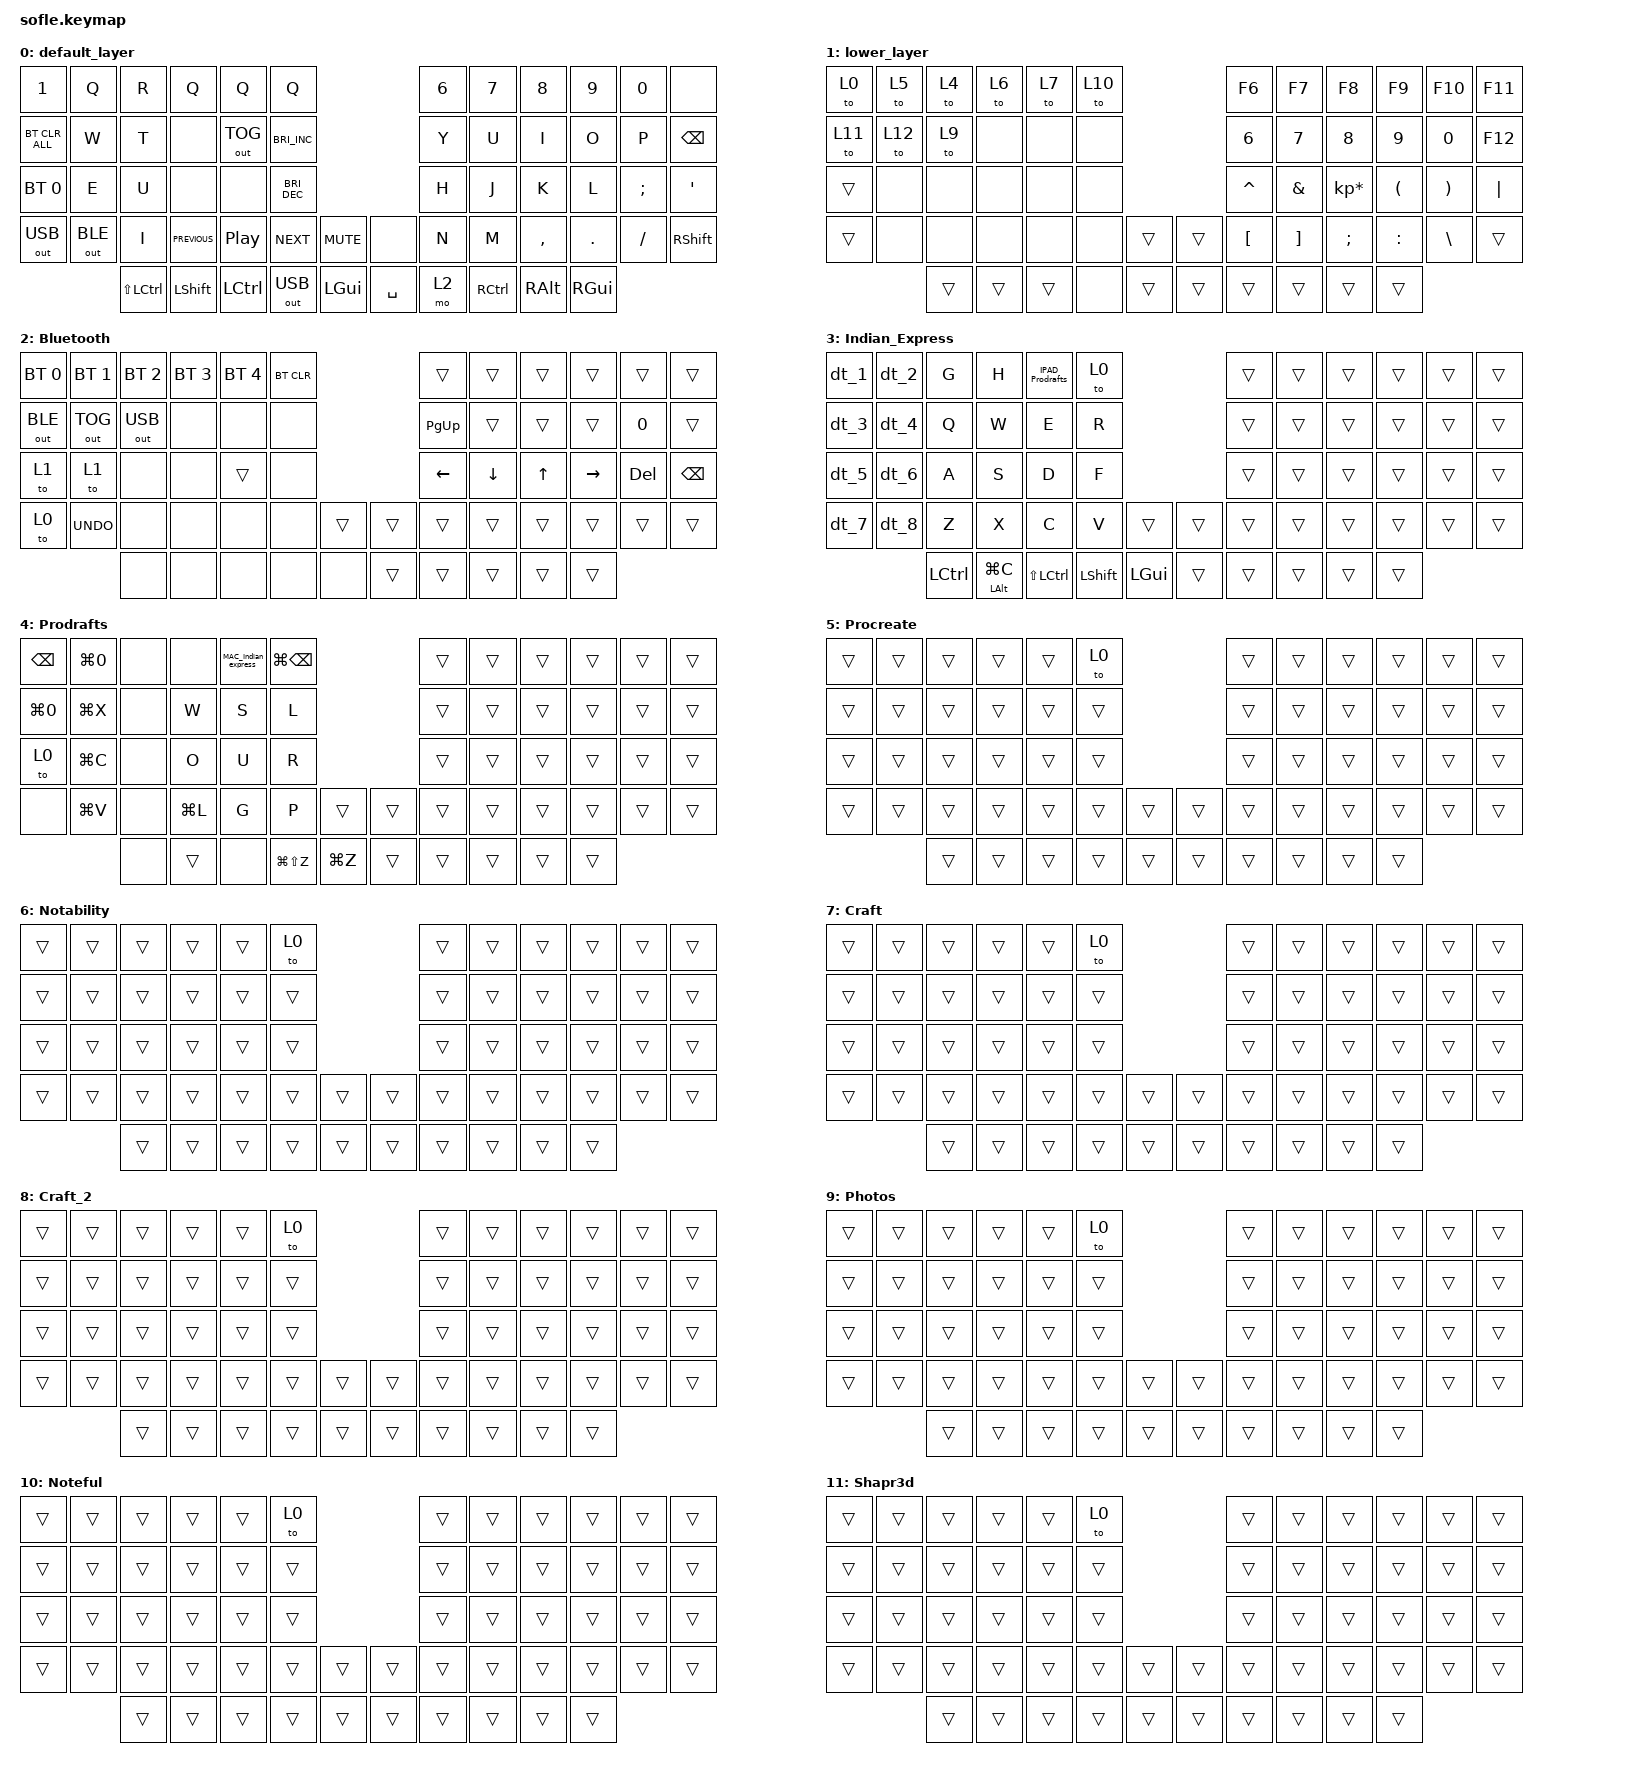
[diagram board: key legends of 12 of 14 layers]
/*
 * Copyright (c) 2020 The ZMK Contributors
 *
 * SPDX-License-Identifier: MIT
 */

#include <behaviors.dtsi>
#include <dt-bindings/zmk/bt.h>
#include <dt-bindings/zmk/keys.h>
#include <dt-bindings/zmk/outputs.h>

/ {
    combos {
        compatible = "zmk,combos";

        combo_capsw {
            timeout-ms = <50>;
            key-positions = <16 19>;
            bindings = <&caps_word>;
        };

        combo_bootl {
            timeout-ms = <50>;
            key-positions = <0 1 2>;
            bindings = <&bootloader>;
        };

        combo_reset {
            timeout-ms = <50>;
            key-positions = <10 11 12>;
            bindings = <&sys_reset>;
        };
    };

    behaviors {
        rot_td: rot_tap_dance {
            compatible = "zmk,behavior-tap-dance";
            #binding-cells = <0>;
            tapping-term-ms = <250>;
            bindings = <&kp C_PP>, <&kp C_NEXT>, <&kp C_PREV>;
        };

        ble_encoder: ble_encoder {
            compatible = "zmk,behavior-sensor-rotate";
            #sensor-binding-cells = <0>;
            bindings = <&bt BT_NXT>, <&bt BT_PRV>;
        };

        dt_1: dt_1 {
            compatible = "zmk,behavior-tap-dance";
            label = "DT_1";
            #binding-cells = <0>;
            tapping-term-ms = <250>;
            bindings = <&kp N0>, <&kp RS(N0)>, <&kp RA(N0)>;
        };

        dt_2: dt_2 {
            compatible = "zmk,behavior-tap-dance";
            label = "DT_2";
            #binding-cells = <0>;
            tapping-term-ms = <250>;
            bindings = <&kp NUMBER_2>, <&kp RS(NUMBER_2)>, <&kp RA(NUMBER_2)>;
        };

        dt_3: dt_3 {
            compatible = "zmk,behavior-tap-dance";
            label = "DT_3";
            #binding-cells = <0>;
            tapping-term-ms = <250>;
            bindings = <&kp NUMBER_3>, <&kp RS(NUMBER_3)>, <&kp RA(NUMBER_3)>;
        };

        dt_0: dt_0 {
            compatible = "zmk,behavior-tap-dance";
            label = "DT_0";
            #binding-cells = <0>;
            tapping-term-ms = <250>;
            bindings = <&kp N0>, <&kp RS(N0)>, <&kp RA(N0)>;
        };

        dt_4: dt_4 {
            compatible = "zmk,behavior-tap-dance";
            label = "DT_4";
            #binding-cells = <0>;
            tapping-term-ms = <250>;
            bindings = <&kp NUMBER_4>, <&kp RS(NUMBER_4)>, <&kp RA(NUMBER_4)>;
        };

        dt_5: dt_5 {
            compatible = "zmk,behavior-tap-dance";
            label = "DT_5";
            #binding-cells = <0>;
            tapping-term-ms = <250>;
            bindings = <&kp N5>, <&kp RS(N5)>, <&kp RA(N5)>;
        };

        dt_6: dt_6 {
            compatible = "zmk,behavior-tap-dance";
            label = "DT_6";
            #binding-cells = <0>;
            tapping-term-ms = <250>;
            bindings = <&kp N6>, <&kp RS(N6)>, <&kp RA(N6)>;
        };

        dt_7: dt_7 {
            compatible = "zmk,behavior-tap-dance";
            label = "DT_7";
            #binding-cells = <0>;
            tapping-term-ms = <250>;
            bindings = <&kp N7>, <&kp RS(N7)>, <&kp RA(N7)>;
        };

        dt_8: dt_8 {
            compatible = "zmk,behavior-tap-dance";
            label = "DT_8";
            #binding-cells = <0>;
            tapping-term-ms = <250>;
            bindings = <&kp N8>, <&kp RS(N8)>, <&kp RA(N8)>;
        };
    };

    macros {
        Craft_insert_new_Drawing: Craft_insert_new_Drawing {
            compatible = "zmk,behavior-macro";
            #binding-cells = <0>;
            bindings = <&kp FSLH &kp I &kp N &kp S &kp E &kp R &kp T &kp SPACE &kp N &kp E &kp W &kp SPACE &kp D &kp R &kp A &kp W &kp I &kp N &kp G &kp RET>;
            label = "CRAFT_INSERT_NEW_DRAWING";
        };

        Craft_Red: Craft_Red {
            compatible = "zmk,behavior-macro";
            #binding-cells = <0>;
            bindings = <&kp FSLH &kp R &kp E &kp D &kp RET>;
            label = "CRAFT_RED";
        };

        Craft_Orange: Craft_Orange {
            compatible = "zmk,behavior-macro";
            #binding-cells = <0>;
            bindings = <&kp FSLH &kp O &kp R &kp A &kp N &kp G &kp E &kp RET>;
            label = "CRAFT_ORANGE";
        };

        Craft_pink: Craft_pink {
            compatible = "zmk,behavior-macro";
            #binding-cells = <0>;
            bindings = <&kp FSLH &kp P &kp I &kp N &kp K &kp RET>;
            label = "CRAFT_PINK";
        };

        Craft_brown: Craft_brown {
            compatible = "zmk,behavior-macro";
            #binding-cells = <0>;
            bindings = <&kp FSLH &kp B &kp R &kp O &kp W &kp N &kp RET>;
            label = "CRAFT_BROWN";
        };

        Craft_Purple: Craft_Purple {
            compatible = "zmk,behavior-macro";
            #binding-cells = <0>;
            bindings = <&kp FSLH &kp P &kp U &kp R &kp P &kp L &kp E &kp RET>;
            label = "CRAFT_PURPLE";
        };

        craft_olive: craft_olive {
            compatible = "zmk,behavior-macro";
            #binding-cells = <0>;
            bindings = <&kp FSLH &kp O &kp L &kp I &kp V &kp E &kp RET>;
            label = "CRAFT_OLIVE";
        };

        craft_Default_color: craft_Default_color {
            compatible = "zmk,behavior-macro";
            #binding-cells = <0>;
            bindings = <&kp FSLH &kp D &kp E &kp F &kp A &kp U &kp L &kp T &kp SPACE &kp C &kp O &kp L &kp O &kp R &kp RET>;
            label = "CRAFT_DEFAULT_COLOR";
        };

        craft_grey: craft_grey {
            compatible = "zmk,behavior-macro";
            #binding-cells = <0>;
            bindings = <&kp FSLH &kp G &kp R &kp E &kp Y &kp RET>;
            label = "CRAFT_GREY";
        };

        craft_light_grey: craft_light_grey {
            compatible = "zmk,behavior-macro";
            #binding-cells = <0>;
            bindings = <&kp FSLH &kp L &kp I &kp G &kp H &kp T &kp SPACE &kp G &kp R &kp E &kp Y &kp RET>;
            label = "CRAFT_LIGHT_GREY";
        };

        craft_navy_blue: craft_navy_blue {
            compatible = "zmk,behavior-macro";
            #binding-cells = <0>;
            bindings = <&kp FSLH &kp N &kp A &kp V &kp Y &kp SPACE &kp B &kp L &kp U &kp E &kp RET>;
            label = "CRAFT_NAVY_BLUE";
        };

        craft_ocean_blue: craft_ocean_blue {
            compatible = "zmk,behavior-macro";
            #binding-cells = <0>;
            bindings = <&kp FSLH &kp O &kp C &kp E &kp A &kp N &kp SPACE &kp B &kp L &kp U &kp E &kp RET>;
            label = "CRAFT_OCEAN_BLUE";
        };

        craft_green: craft_green {
            compatible = "zmk,behavior-macro";
            #binding-cells = <0>;
            bindings = <&kp FSLH &kp G &kp R &kp E &kp E &kp N &kp RET>;
            label = "CRAFT_GREEN";
        };

        craft_table: craft_table {
            compatible = "zmk,behavior-macro";
            #binding-cells = <0>;
            bindings = <&kp FSLH &kp T &kp A &kp B &kp L &kp E>;
            label = "CRAFT_TABLE";
        };

        craft_clear_style: craft_clear_style {
            compatible = "zmk,behavior-macro";
            #binding-cells = <0>;
            bindings = <&kp FSLH &kp C &kp L &kp E &kp A &kp R &kp SPACE &kp S &kp T &kp Y &kp L &kp I &kp N &kp G &kp RET>;
            label = "CRAFT_CLEAR_STYLE";
        };

        Craft_page_break: Craft_page_break {
            compatible = "zmk,behavior-macro";
            #binding-cells = <0>;
            bindings = <&kp FSLH &kp P &kp A &kp G &kp E &kp SPACE &kp B &kp R &kp E &kp A &kp K>;
            label = "CRAFT_PAGE_BREAK";
        };

        Craft_move_to: Craft_move_to {
            compatible = "zmk,behavior-macro";
            #binding-cells = <0>;
            bindings = <&kp FSLH &kp M &kp O &kp V &kp E &kp SPACE &kp T &kp O &kp RET>;
            label = "CRAFT_MOVE_TO";
        };

        craft_image: craft_image {
            compatible = "zmk,behavior-macro";
            #binding-cells = <0>;
            bindings = <&kp FSLH &kp I &kp M &kp A &kp G &kp E>;
            label = "CRAFT_IMAGE";
        };

        MAC_Indian_express: MAC_Indian_express {
            compatible = "zmk,behavior-macro";
            #binding-cells = <0>;
            bindings = <&bt BT_SEL 0>, <&macro_wait_time 400>, <&to 3>;

            label = "MAC_INDIAN_EXPRESS";
        };

        IPAD_Prodrafts: IPAD_Prodrafts {
            compatible = "zmk,behavior-macro";
            #binding-cells = <0>;
            bindings = <&bt BT_SEL 1>, <&macro_wait_time 400>, <&to 4>;

            label = "IPAD_PRODRAFTS";
        };
    };

    keymap {
        compatible = "zmk,keymap";

        default_layer {
            // ------------------------------------------------------------------------------------------------------------
            // |  `    |  1  |  2  |  3   |  4   |  5   |                   |  6   |  7    |  8    |  9   |   0   |       |
            // |  ESC  |  Q  |  W  |  E   |  R   |  T   |                   |  Y   |  U    |  I    |  O   |   P   | BKSPC |
            // |  TAB  |  A  |  S  |  D   |  F   |  G   |                   |  H   |  J    |  K    |  L   |   ;   |   '   |
            // | SHIFT |  Z  |  X  |  C   |  V   |  B   |  MUTE  |  |       |  N   |  M    |  ,    |  .   |   /   | SHIFT |
            //               | GUI | ALT  | CTRL | LOWER|  ENTER |  | SPACE | RAISE| CTRL  | ALT   | GUI  |

            bindings = <
&kp NUMBER_1    &kp Q         &kp R                 &kp Q           &kp Q             &kp Q                                            &kp N6  &kp N7     &kp N8     &kp N9    &kp N0    &none
&bt BT_CLR_ALL  &kp W         &kp T                 &none           &out OUT_TOG      &kp C_BRIGHTNESS_INC                             &kp Y   &kp U      &kp I      &kp O     &kp P     &kp BSPC
&bt BT_SEL 0    &kp E         &kp U                 &none           &none             &kp C_BRIGHTNESS_DEC                             &kp H   &kp J      &kp K      &kp L     &kp SEMI  &kp SQT
&out OUT_USB    &out OUT_BLE  &kp I                 &kp C_PREVIOUS  &kp C_PLAY_PAUSE  &kp C_NEXT            &kp C_MUTE      &none      &kp N   &kp M      &kp COMMA  &kp DOT   &kp FSLH  &kp RSHFT
                              &kp LS(LEFT_CONTROL)  &kp LEFT_SHIFT  &kp LCTRL         &out OUT_USB          &kp LEFT_GUI    &kp SPACE  &mo 2   &kp RCTRL  &kp RALT   &kp RGUI
            >;

            sensor-bindings =
                <&inc_dec_kp C_VOLUME_UP C_VOLUME_DOWN>,
                <&inc_dec_kp PG_UP PG_DN>;
        };

        lower_layer {
            // TODO: Some binds are waiting for shifted keycode support.
            // ------------------------------------------------------------------------------------------------------------
            // |       |  F1 |  F2 |  F3  |  F4  |  F5  |                   |  F6  |  F7   |  F8   |  F9  |  F10  |  F11  |
            // | `     |   1 |   2 |   3  |   4  |   5  |                   |   6  |   7   |   8   |   9  |    0  |  F12  |
            // |       |  !  |  @  |  #   |  $   |  %   |                   |  ^   |  &    |  *    |  (   |   )   |   |   |
            // |       |  =  |  -  |  +   |  {   |  }   |        |  |       |  [   |  ]    |  ;    |  :   |   \   |       |
            //               |     |      |      |      |        |  |       |      |       |       |      |

            bindings = <
&to 0   &to 5   &to 4   &to 6   &to 7   &to 10                    &kp F6     &kp F7    &kp F8           &kp F9     &kp F10   &kp F11
&to 11  &to 12  &to 9   &none   &none   &none                     &kp N6     &kp N7    &kp N8           &kp N9     &kp N0    &kp F12
&trans  &none   &none   &none   &none   &none                     &kp CARET  &kp AMPS  &kp KP_MULTIPLY  &kp LPAR   &kp RPAR  &kp PIPE
&trans  &none   &none   &none   &none   &none   &trans    &trans  &kp LBKT   &kp RBKT  &kp SEMI         &kp COLON  &kp BSLH  &trans
                &trans  &trans  &trans  &none   &trans    &trans  &trans     &trans    &trans           &trans
            >;

            sensor-bindings =
                <&inc_dec_kp C_VOLUME_DOWN C_VOLUME_UP>,
                <&inc_dec_kp PG_UP PG_DN>;
        };

        Bluetooth {
            // ------------------------------------------------------------------------------------------------------------
            // |BTCLR| BT1  | BT2  |  BT3  |  BT4  |  BT5 |                |      |      |       |      |       |       |
            // |     | INS  | PSCR | GUI   |       |      |                | PGUP |      |       |      |       |       |
            // |     | ALT  | CTRL | SHIFT |       | CAPS |                |  <-  |   v  |   ^   |  ->  |  DEL  | BKSPC |
            // |     | UNDO | CUT  | COPY  | PASTE |      |      |  |      |      |      |       |      |       |       |
            //              |      |       |       |      |      |  |      |      |      |       |      |

            bindings = <
&bt BT_SEL 0  &bt BT_SEL 1  &bt BT_SEL 2  &bt BT_SEL 3  &bt BT_SEL 4  &bt BT_CLR                    &trans     &trans    &trans  &trans     &trans   &trans
&out OUT_BLE  &out OUT_TOG  &out OUT_USB  &none         &none         &none                         &kp PG_UP  &trans    &trans  &trans     &kp N0   &trans
&to 1         &to 1         &none         &none         &trans        &none                         &kp LEFT   &kp DOWN  &kp UP  &kp RIGHT  &kp DEL  &kp BSPC
&to 0         &kp K_UNDO    &none         &none         &none         &none       &trans    &trans  &trans     &trans    &trans  &trans     &trans   &trans
                            &none         &none         &none         &none       &none     &trans  &trans     &trans    &trans  &trans
            >;

            sensor-bindings = <&inc_dec_kp C_VOL_UP C_VOL_DN &inc_dec_kp PG_UP PG_DN>;
        };

        Indian_Express {
            bindings = <
&dt_1  &dt_2  &kp G             &kp H               &IPAD_Prodrafts       &to 0                                   &trans  &trans  &trans  &trans  &trans  &trans
&dt_3  &dt_4  &kp Q             &kp W               &kp E                 &kp R                                   &trans  &trans  &trans  &trans  &trans  &trans
&dt_5  &dt_6  &kp A             &kp S               &kp D                 &kp F                                   &trans  &trans  &trans  &trans  &trans  &trans
&dt_7  &dt_8  &kp Z             &kp X               &kp C                 &kp V           &trans          &trans  &trans  &trans  &trans  &trans  &trans  &trans
              &kp LEFT_CONTROL  &mt LEFT_ALT LG(C)  &kp LS(LEFT_CONTROL)  &kp LEFT_SHIFT  &kp LEFT_GUI    &trans  &trans  &trans  &trans  &trans
            >;

            sensor-bindings = <&inc_dec_kp UP_ARROW DOWN_ARROW>;
        };

        Prodrafts {
            bindings = <
&kp BACKSPACE  &kp LG(N0)  &none  &none      &MAC_Indian_express  &kp LG(BACKSPACE)                       &trans  &trans  &trans  &trans  &trans  &trans
&kp LG(N0)     &kp LG(X)   &none  &kp W      &kp S                &kp L                                   &trans  &trans  &trans  &trans  &trans  &trans
&to 0          &kp LG(C)   &none  &kp O      &kp U                &kp R                                   &trans  &trans  &trans  &trans  &trans  &trans
&none          &kp LG(V)   &none  &kp LG(L)  &kp G                &kp P              &trans       &trans  &trans  &trans  &trans  &trans  &trans  &trans
                           &none  &trans     &none                &kp LG(LS(Z))      &kp LG(Z)    &trans  &trans  &trans  &trans  &trans
            >;

            sensor-bindings = <&inc_dec_kp LG(MINUS) LG(EQUAL)>;
        };

        Procreate {
            bindings = <
&trans  &trans  &trans  &trans  &trans  &to 0                     &trans  &trans  &trans  &trans  &trans  &trans
&trans  &trans  &trans  &trans  &trans  &trans                    &trans  &trans  &trans  &trans  &trans  &trans
&trans  &trans  &trans  &trans  &trans  &trans                    &trans  &trans  &trans  &trans  &trans  &trans
&trans  &trans  &trans  &trans  &trans  &trans  &trans    &trans  &trans  &trans  &trans  &trans  &trans  &trans
                &trans  &trans  &trans  &trans  &trans    &trans  &trans  &trans  &trans  &trans
            >;
        };

        Notability {
            bindings = <
&trans  &trans  &trans  &trans  &trans  &to 0                     &trans  &trans  &trans  &trans  &trans  &trans
&trans  &trans  &trans  &trans  &trans  &trans                    &trans  &trans  &trans  &trans  &trans  &trans
&trans  &trans  &trans  &trans  &trans  &trans                    &trans  &trans  &trans  &trans  &trans  &trans
&trans  &trans  &trans  &trans  &trans  &trans  &trans    &trans  &trans  &trans  &trans  &trans  &trans  &trans
                &trans  &trans  &trans  &trans  &trans    &trans  &trans  &trans  &trans  &trans
            >;
        };

        Craft {
            bindings = <
&trans  &trans  &trans  &trans  &trans  &to 0                     &trans  &trans  &trans  &trans  &trans  &trans
&trans  &trans  &trans  &trans  &trans  &trans                    &trans  &trans  &trans  &trans  &trans  &trans
&trans  &trans  &trans  &trans  &trans  &trans                    &trans  &trans  &trans  &trans  &trans  &trans
&trans  &trans  &trans  &trans  &trans  &trans  &trans    &trans  &trans  &trans  &trans  &trans  &trans  &trans
                &trans  &trans  &trans  &trans  &trans    &trans  &trans  &trans  &trans  &trans
            >;
        };

        Craft_2 {
            bindings = <
&trans  &trans  &trans  &trans  &trans  &to 0                     &trans  &trans  &trans  &trans  &trans  &trans
&trans  &trans  &trans  &trans  &trans  &trans                    &trans  &trans  &trans  &trans  &trans  &trans
&trans  &trans  &trans  &trans  &trans  &trans                    &trans  &trans  &trans  &trans  &trans  &trans
&trans  &trans  &trans  &trans  &trans  &trans  &trans    &trans  &trans  &trans  &trans  &trans  &trans  &trans
                &trans  &trans  &trans  &trans  &trans    &trans  &trans  &trans  &trans  &trans
            >;
        };

        Photos {
            bindings = <
&trans  &trans  &trans  &trans  &trans  &to 0                     &trans  &trans  &trans  &trans  &trans  &trans
&trans  &trans  &trans  &trans  &trans  &trans                    &trans  &trans  &trans  &trans  &trans  &trans
&trans  &trans  &trans  &trans  &trans  &trans                    &trans  &trans  &trans  &trans  &trans  &trans
&trans  &trans  &trans  &trans  &trans  &trans  &trans    &trans  &trans  &trans  &trans  &trans  &trans  &trans
                &trans  &trans  &trans  &trans  &trans    &trans  &trans  &trans  &trans  &trans
            >;
        };

        Noteful {
            bindings = <
&trans  &trans  &trans  &trans  &trans  &to 0                     &trans  &trans  &trans  &trans  &trans  &trans
&trans  &trans  &trans  &trans  &trans  &trans                    &trans  &trans  &trans  &trans  &trans  &trans
&trans  &trans  &trans  &trans  &trans  &trans                    &trans  &trans  &trans  &trans  &trans  &trans
&trans  &trans  &trans  &trans  &trans  &trans  &trans    &trans  &trans  &trans  &trans  &trans  &trans  &trans
                &trans  &trans  &trans  &trans  &trans    &trans  &trans  &trans  &trans  &trans
            >;
        };

        Shapr3d {
            bindings = <
&trans  &trans  &trans  &trans  &trans  &to 0                     &trans  &trans  &trans  &trans  &trans  &trans
&trans  &trans  &trans  &trans  &trans  &trans                    &trans  &trans  &trans  &trans  &trans  &trans
&trans  &trans  &trans  &trans  &trans  &trans                    &trans  &trans  &trans  &trans  &trans  &trans
&trans  &trans  &trans  &trans  &trans  &trans  &trans    &trans  &trans  &trans  &trans  &trans  &trans  &trans
                &trans  &trans  &trans  &trans  &trans    &trans  &trans  &trans  &trans  &trans
            >;
        };

        concepts {
            bindings = <
&trans  &trans  &trans  &trans  &trans  &to 0                     &trans  &trans  &trans  &trans  &trans  &trans
&trans  &trans  &trans  &trans  &trans  &trans                    &trans  &trans  &trans  &trans  &trans  &trans
&trans  &trans  &trans  &trans  &trans  &trans                    &trans  &trans  &trans  &trans  &trans  &trans
&trans  &trans  &trans  &trans  &trans  &trans  &trans    &trans  &trans  &trans  &trans  &trans  &trans  &trans
                &trans  &trans  &trans  &trans  &trans    &trans  &trans  &trans  &trans  &trans
            >;
        };

        Mac_Apps {
            bindings = <
&to 3   &trans  &trans  &trans  &trans  &to 0                     &trans  &trans  &trans  &trans  &trans  &trans
&trans  &trans  &trans  &trans  &trans  &trans                    &trans  &trans  &trans  &trans  &trans  &trans
&trans  &trans  &trans  &trans  &trans  &trans                    &trans  &trans  &trans  &trans  &trans  &trans
&trans  &trans  &trans  &trans  &trans  &trans  &trans    &trans  &trans  &trans  &trans  &trans  &trans  &trans
                &trans  &trans  &trans  &trans  &trans    &trans  &trans  &trans  &trans  &trans
            >;
        };
    };
};
